# SA3_SS0_SEC_PROXY_0_IPCSS_SEC_PROXY_CFG_MMRS register map
Vendor: Texas Instruments
Peripheral module from a debugger description file (folder am62P).
Registers are 32-bit, read-only, reset 0x66367100 unless marked. A register's access mark holds for its fields unless they carry their own. Offsets are as the file gives them; lines under a group give offsets from that group; [hi:lo] are bit positions; {n}, {i} and the like mark numbered series; 'fields as' and 'values as' point back to an identical list; <NAME> marks a mode.

## SA3_SS0_SEC_PROXY_0_IPCSS_SEC_PROXY_CFG_MMRS
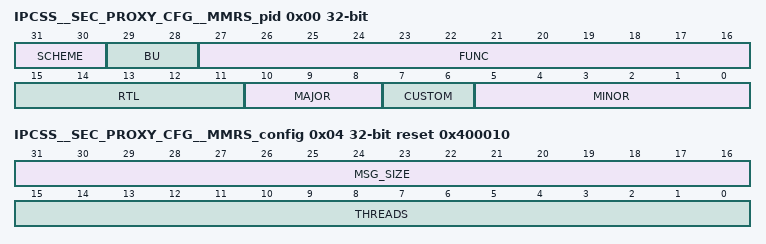
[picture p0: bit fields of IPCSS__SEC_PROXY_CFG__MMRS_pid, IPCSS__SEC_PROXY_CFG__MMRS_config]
0x00 IPCSS__SEC_PROXY_CFG__MMRS_pid — The Revision Register contains the major and minor revisions for the module.
  [31:30] SCHEME — PID register scheme
  [29:28] BU — Business Unit: 10 = Processors
  [27:16] FUNC — Module ID
  [15:11] RTL — RTL revision. Will vary depending on release.
  [10:8] MAJOR — Major revision
  [7:6] CUSTOM
  [5:0] MINOR — Minor revision
0x04 IPCSS__SEC_PROXY_CFG__MMRS_config reset 0x400010 — The Config Register shows configured params.
  [31:16] MSG_SIZE — Supported message size in bytes.
  [15:0] THREADS — Number of proxy threads supported.
0x14 IPCSS__SEC_PROXY_CFG__MMRS_glb_evt rw reset 0xFFFF — The Global Event Register defines the event to send for a global error.
  [15:0] ERR_EVENT — Global error event destination. 0xFFFF disables the event
